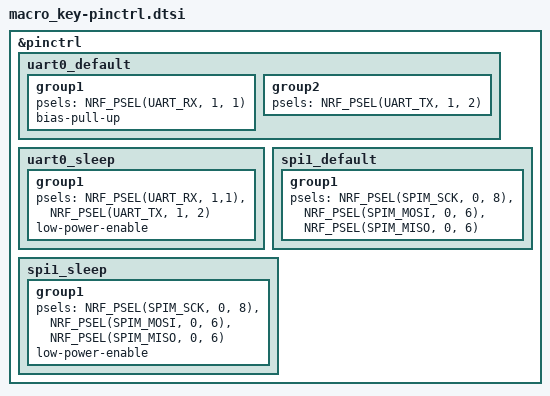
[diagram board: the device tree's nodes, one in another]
/*
 * Copyright (c) 2022 The ZMK Contributors
 * SPDX-License-Identifier: MIT
 */

&pinctrl {
    uart0_default: uart0_default {
        group1 {
            psels = <NRF_PSEL(UART_RX, 1, 1)>;
            bias-pull-up;
        };
        group2 {
            psels = <NRF_PSEL(UART_TX, 1, 2)>;
        };
    };

    uart0_sleep: uart0_sleep {
        group1 {
            psels = <NRF_PSEL(UART_RX, 1,1)>,
                <NRF_PSEL(UART_TX, 1, 2)>;
            low-power-enable;
        };
    };
    
    spi1_default: spi1_default {
        group1 {
            psels = <NRF_PSEL(SPIM_SCK, 0, 8)>,
                <NRF_PSEL(SPIM_MOSI, 0, 6)>,
                <NRF_PSEL(SPIM_MISO, 0, 6)>;
        };
    };

    spi1_sleep: spi1_sleep {
        group1 {
            psels = <NRF_PSEL(SPIM_SCK, 0, 8)>,
                <NRF_PSEL(SPIM_MOSI, 0, 6)>,
                <NRF_PSEL(SPIM_MISO, 0, 6)>;
            low-power-enable;
        };
    };
};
